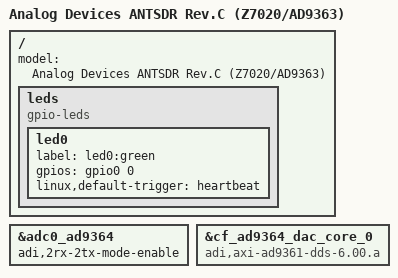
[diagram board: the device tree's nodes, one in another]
// SPDX-License-Identifier: GPL-2.0
/*
 *
 * hdl_project: <ant>
 * board_revision: <A>
 *
 * Copyright (C) 2016-2019 MicroPhase Inc.
 */
/dts-v1/;
#include "zynq-e200.dtsi"



&adc0_ad9364 {
	/* This property is controlled by u-boot environment. */
	adi,2rx-2tx-mode-enable;
};

&cf_ad9364_dac_core_0 {
	/* This property is controlled by u-boot environment. */
	compatible = "adi,axi-ad9361-dds-6.00.a";
};


/ {
	model = "Analog Devices ANTSDR Rev.C (Z7020/AD9363)";
	
	leds {
		compatible = "gpio-leds";
		led0 {
			label = "led0:green";
			gpios = <&gpio0 0 0>;
			linux,default-trigger = "heartbeat";
		};
	};
};
